# CTRL_MODULE_CORE register map
Vendor: Texas Instruments
Registers are 32-bit, access per field, reset 0x0 unless marked. A register's access mark holds for its fields unless they carry their own. Offsets are as the file gives them; [hi:lo] are bit positions; {n}, {i} and the like mark numbered series; 'fields as' and 'values as' point back to an identical list.

## CTRL_MODULE_CORE (part 12 of 12)
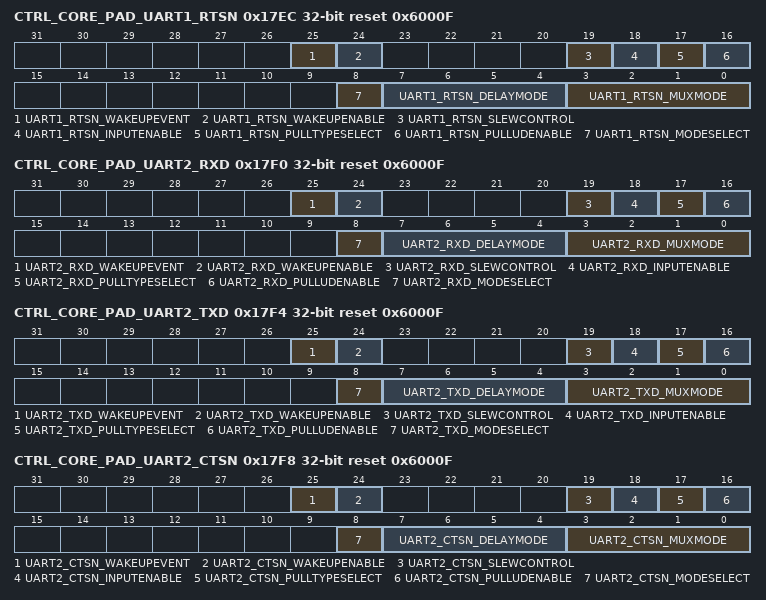
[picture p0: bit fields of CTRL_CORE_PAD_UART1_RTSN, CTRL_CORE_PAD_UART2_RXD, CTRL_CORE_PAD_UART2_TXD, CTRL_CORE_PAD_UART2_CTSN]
0x17EC CTRL_CORE_PAD_UART1_RTSN reset 0x6000F
  [25] UART1_RTSN_WAKEUPEVENT ro
    0=NOWAKEUP (No wakeup event detected); 1=WAKEUP (Wakeup event detected)
  [24] UART1_RTSN_WAKEUPENABLE rw
    0=DISABLE (Wakeup is disabled); 1=ENABLE (Wakeup is enabled)
  [19] UART1_RTSN_SLEWCONTROL rw
    0=FAST_SLEW (Fast slew is selected); 1=SLOW_SLEW (Slow slew is selected)
  [18] UART1_RTSN_INPUTENABLE rw
    0=DISABLE (Receive mode is disabled); 1=ENABLE (Receive mode is enabled)
  [17] UART1_RTSN_PULLTYPESELECT rw
    0=PULL_DOWN (Pull Down is selected); 1=PULL_UP (Pull Up is selected)
  [16] UART1_RTSN_PULLUDENABLE rw
    0=ENABLE (Enables weak Pull Up/Down); 1=DISABLE (Disables weak Pull Up/Down)
  [8] UART1_RTSN_MODESELECT rw — Selects between the Default IO Timing Mode and a Virtual or Manual IO Timing Mode. Refer to the device Data Manual for definition of the required settings for a given mode of operation. When this bit is 0b1, a Virtual IO Timing Mode can be selected via the DELAYMODE field of this register, as described in, Virtual IO Timing Modes. Manual IO Timing Modes are selected via the procedure described in , Manual IO Timing Modes.
    0=MUX_MODE (Default IO Timing Mode is used); 1=DELAY_MODE (A Virtual or Manual IO Timing Mode is used)
  [7:4] UART1_RTSN_DELAYMODE rw — This bit field selects the Virtual Timing Mode used when the MODESELECT bit is set to 0b1. See, Virtual IO Timing Modes for details.
  [3:0] UART1_RTSN_MUXMODE rw
    0=UART1_RTSN; 2=UART9_TXD; 3=MMC4_CMD; 14=GPIO7_25; 15=DRIVER OFF
0x17F0 CTRL_CORE_PAD_UART2_RXD reset 0x6000F
  [25] UART2_RXD_WAKEUPEVENT ro
    values as CTRL_CORE_PAD_UART1_RTSN.UART1_RTSN_WAKEUPEVENT
  [24] UART2_RXD_WAKEUPENABLE rw
    0=DISABLE (Wakeup is disabled); 1=ENABLE (Wakeup is enabled)
  [19] UART2_RXD_SLEWCONTROL rw
    values as CTRL_CORE_PAD_UART1_RTSN.UART1_RTSN_SLEWCONTROL
  [18] UART2_RXD_INPUTENABLE rw
    values as CTRL_CORE_PAD_UART1_RTSN.UART1_RTSN_INPUTENABLE
  [17] UART2_RXD_PULLTYPESELECT rw
    values as CTRL_CORE_PAD_UART1_RTSN.UART1_RTSN_PULLTYPESELECT
  [16] UART2_RXD_PULLUDENABLE rw
    values as CTRL_CORE_PAD_UART1_RTSN.UART1_RTSN_PULLUDENABLE
  [8] UART2_RXD_MODESELECT rw — Selects between the Default IO Timing Mode and a Virtual or Manual IO Timing Mode. Refer to the device Data Manual for definition of the required settings for a given mode of operation. When this bit is 0b1, a Virtual IO Timing Mode can be selected via the DELAYMODE field of this register, as described in, Virtual IO Timing Modes. Manual IO Timing Modes are selected via the procedure described in , Manual IO Timing Modes.
    values as CTRL_CORE_PAD_UART1_RTSN.UART1_RTSN_MODESELECT
  [7:4] UART2_RXD_DELAYMODE rw — This bit field selects the Virtual Timing Mode used when the MODESELECT bit is set to 0b1. See, Virtual IO Timing Modes for details.
  [3:0] UART2_RXD_MUXMODE rw
    1=UART3_CTSN; 2=UART3_RCTX; 3=MMC4_DAT0; 4=UART2_RXD; 5=UART1_DCDN; 14=GPIO7_26; 15=DRIVER OFF
0x17F4 CTRL_CORE_PAD_UART2_TXD reset 0x6000F
  [25] UART2_TXD_WAKEUPEVENT ro
    values as CTRL_CORE_PAD_UART1_RTSN.UART1_RTSN_WAKEUPEVENT
  [24] UART2_TXD_WAKEUPENABLE rw
    0=DISABLE (Wakeup is disabled); 1=ENABLE (Wakeup is enabled)
  [19] UART2_TXD_SLEWCONTROL rw
    values as CTRL_CORE_PAD_UART1_RTSN.UART1_RTSN_SLEWCONTROL
  [18] UART2_TXD_INPUTENABLE rw
    values as CTRL_CORE_PAD_UART1_RTSN.UART1_RTSN_INPUTENABLE
  [17] UART2_TXD_PULLTYPESELECT rw
    values as CTRL_CORE_PAD_UART1_RTSN.UART1_RTSN_PULLTYPESELECT
  [16] UART2_TXD_PULLUDENABLE rw
    values as CTRL_CORE_PAD_UART1_RTSN.UART1_RTSN_PULLUDENABLE
  [8] UART2_TXD_MODESELECT rw — Selects between the Default IO Timing Mode and a Virtual or Manual IO Timing Mode. Refer to the device Data Manual for definition of the required settings for a given mode of operation. When this bit is 0b1, a Virtual IO Timing Mode can be selected via the DELAYMODE field of this register, as described in, Virtual IO Timing Modes. Manual IO Timing Modes are selected via the procedure described in , Manual IO Timing Modes.
    values as CTRL_CORE_PAD_UART1_RTSN.UART1_RTSN_MODESELECT
  [7:4] UART2_TXD_DELAYMODE rw — This bit field selects the Virtual Timing Mode used when the MODESELECT bit is set to 0b1. See, Virtual IO Timing Modes for details.
  [3:0] UART2_TXD_MUXMODE rw
    0=UART2_TXD; 1=UART3_RTSN; 2=UART3_SD; 3=MMC4_DAT1; 4=UART2_TXD; 5=UART1_DSRN; 14=GPIO7_27; 15=DRIVER OFF
0x17F8 CTRL_CORE_PAD_UART2_CTSN reset 0x6000F
  [25] UART2_CTSN_WAKEUPEVENT ro
    values as CTRL_CORE_PAD_UART1_RTSN.UART1_RTSN_WAKEUPEVENT
  [24] UART2_CTSN_WAKEUPENABLE rw
    0=DISABLE (Wakeup is disabled); 1=ENABLE (Wakeup is enabled)
  [19] UART2_CTSN_SLEWCONTROL rw
    values as CTRL_CORE_PAD_UART1_RTSN.UART1_RTSN_SLEWCONTROL
  [18] UART2_CTSN_INPUTENABLE rw
    values as CTRL_CORE_PAD_UART1_RTSN.UART1_RTSN_INPUTENABLE
  [17] UART2_CTSN_PULLTYPESELECT rw
    values as CTRL_CORE_PAD_UART1_RTSN.UART1_RTSN_PULLTYPESELECT
  [16] UART2_CTSN_PULLUDENABLE rw
    values as CTRL_CORE_PAD_UART1_RTSN.UART1_RTSN_PULLUDENABLE
  [8] UART2_CTSN_MODESELECT rw — Selects between the Default IO Timing Mode and a Virtual or Manual IO Timing Mode. Refer to the device Data Manual for definition of the required settings for a given mode of operation. When this bit is 0b1, a Virtual IO Timing Mode can be selected via the DELAYMODE field of this register, as described in, Virtual IO Timing Modes. Manual IO Timing Modes are selected via the procedure described in , Manual IO Timing Modes.
    values as CTRL_CORE_PAD_UART1_RTSN.UART1_RTSN_MODESELECT
  [7:4] UART2_CTSN_DELAYMODE rw — This bit field selects the Virtual Timing Mode used when the MODESELECT bit is set to 0b1. See, Virtual IO Timing Modes for details.
  [3:0] UART2_CTSN_MUXMODE rw
    0=UART2_CTSN; 2=UART3_RXD; 3=MMC4_DAT2; 4=UART10_RXD; 5=UART1_DTRN; 14=GPIO1_16; 15=DRIVER OFF
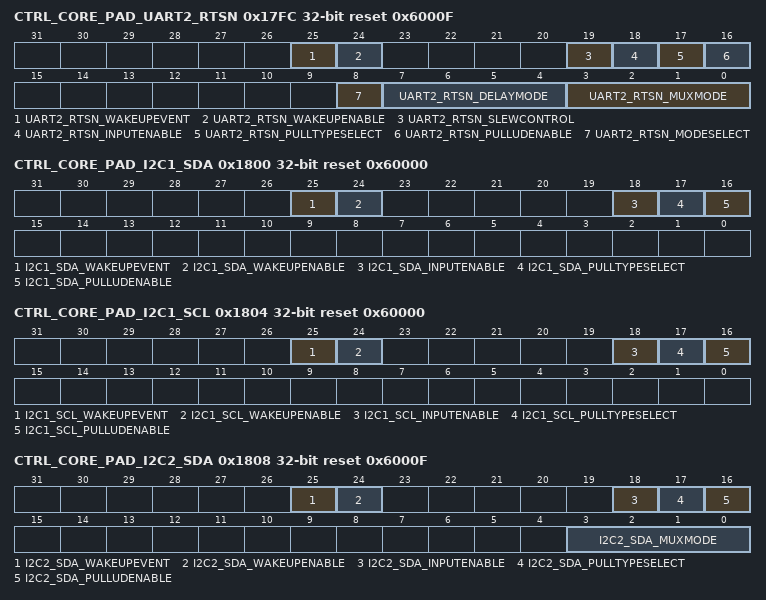
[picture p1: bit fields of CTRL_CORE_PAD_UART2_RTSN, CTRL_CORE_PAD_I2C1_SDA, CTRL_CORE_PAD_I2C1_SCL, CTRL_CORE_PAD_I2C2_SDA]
0x17FC CTRL_CORE_PAD_UART2_RTSN reset 0x6000F
  [25] UART2_RTSN_WAKEUPEVENT ro
    values as CTRL_CORE_PAD_UART1_RTSN.UART1_RTSN_WAKEUPEVENT
  [24] UART2_RTSN_WAKEUPENABLE rw
    0=DISABLE (Wakeup is disabled); 1=ENABLE (Wakeup is enabled)
  [19] UART2_RTSN_SLEWCONTROL rw
    values as CTRL_CORE_PAD_UART1_RTSN.UART1_RTSN_SLEWCONTROL
  [18] UART2_RTSN_INPUTENABLE rw
    values as CTRL_CORE_PAD_UART1_RTSN.UART1_RTSN_INPUTENABLE
  [17] UART2_RTSN_PULLTYPESELECT rw
    values as CTRL_CORE_PAD_UART1_RTSN.UART1_RTSN_PULLTYPESELECT
  [16] UART2_RTSN_PULLUDENABLE rw
    values as CTRL_CORE_PAD_UART1_RTSN.UART1_RTSN_PULLUDENABLE
  [8] UART2_RTSN_MODESELECT rw — Selects between the Default IO Timing Mode and a Virtual or Manual IO Timing Mode. Refer to the device Data Manual for definition of the required settings for a given mode of operation. When this bit is 0b1, a Virtual IO Timing Mode can be selected via the DELAYMODE field of this register, as described in, Virtual IO Timing Modes. Manual IO Timing Modes are selected via the procedure described in , Manual IO Timing Modes.
    values as CTRL_CORE_PAD_UART1_RTSN.UART1_RTSN_MODESELECT
  [7:4] UART2_RTSN_DELAYMODE rw — This bit field selects the Virtual Timing Mode used when the MODESELECT bit is set to 0b1. See, Virtual IO Timing Modes for details.
  [3:0] UART2_RTSN_MUXMODE rw
    0=UART2_RTSN; 1=UART3_TXD; 2=UART3_IRTX; 3=MMC4_DAT3; 4=UART10_TXD; 5=UART1_RIN; 14=GPIO1_17; 15=DRIVER OFF
0x1800 CTRL_CORE_PAD_I2C1_SDA reset 0x60000
  [25] I2C1_SDA_WAKEUPEVENT ro
    values as CTRL_CORE_PAD_UART1_RTSN.UART1_RTSN_WAKEUPEVENT
  [24] I2C1_SDA_WAKEUPENABLE rw
    0=DISABLE (Wakeup is disabled); 1=ENABLE (Wakeup is enabled)
  [18] I2C1_SDA_INPUTENABLE rw
    values as CTRL_CORE_PAD_UART1_RTSN.UART1_RTSN_INPUTENABLE
  [17] I2C1_SDA_PULLTYPESELECT rw
    values as CTRL_CORE_PAD_UART1_RTSN.UART1_RTSN_PULLTYPESELECT
  [16] I2C1_SDA_PULLUDENABLE rw
    values as CTRL_CORE_PAD_UART1_RTSN.UART1_RTSN_PULLUDENABLE
0x1804 CTRL_CORE_PAD_I2C1_SCL reset 0x60000
  [25] I2C1_SCL_WAKEUPEVENT ro
    values as CTRL_CORE_PAD_UART1_RTSN.UART1_RTSN_WAKEUPEVENT
  [24] I2C1_SCL_WAKEUPENABLE rw
    0=DISABLE (Wakeup is disabled); 1=ENABLE (Wakeup is enabled)
  [18] I2C1_SCL_INPUTENABLE rw
    values as CTRL_CORE_PAD_UART1_RTSN.UART1_RTSN_INPUTENABLE
  [17] I2C1_SCL_PULLTYPESELECT rw
    values as CTRL_CORE_PAD_UART1_RTSN.UART1_RTSN_PULLTYPESELECT
  [16] I2C1_SCL_PULLUDENABLE rw
    values as CTRL_CORE_PAD_UART1_RTSN.UART1_RTSN_PULLUDENABLE
0x1808 CTRL_CORE_PAD_I2C2_SDA reset 0x6000F
  [25] I2C2_SDA_WAKEUPEVENT ro
    values as CTRL_CORE_PAD_UART1_RTSN.UART1_RTSN_WAKEUPEVENT
  [24] I2C2_SDA_WAKEUPENABLE rw
    0=DISABLE (Wakeup is disabled); 1=ENABLE (Wakeup is enabled)
  [18] I2C2_SDA_INPUTENABLE rw
    values as CTRL_CORE_PAD_UART1_RTSN.UART1_RTSN_INPUTENABLE
  [17] I2C2_SDA_PULLTYPESELECT rw
    values as CTRL_CORE_PAD_UART1_RTSN.UART1_RTSN_PULLTYPESELECT
  [16] I2C2_SDA_PULLUDENABLE rw
    values as CTRL_CORE_PAD_UART1_RTSN.UART1_RTSN_PULLUDENABLE
  [3:0] I2C2_SDA_MUXMODE rw
    0=I2C2_SDA; 1=HDMI1_DDC_SCL; 15=DRIVER OFF
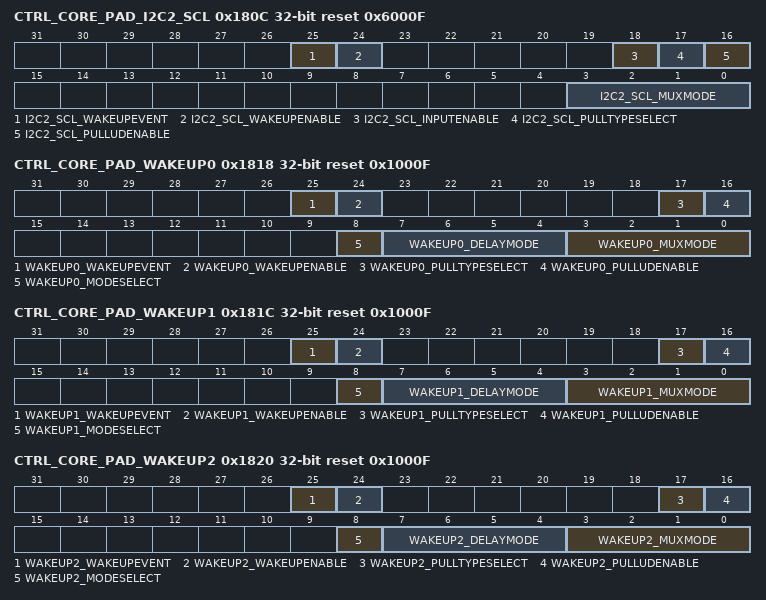
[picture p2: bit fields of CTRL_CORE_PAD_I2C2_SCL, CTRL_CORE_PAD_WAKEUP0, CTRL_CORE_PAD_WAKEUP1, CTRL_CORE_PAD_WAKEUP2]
0x180C CTRL_CORE_PAD_I2C2_SCL reset 0x6000F
  [25] I2C2_SCL_WAKEUPEVENT ro
    values as CTRL_CORE_PAD_UART1_RTSN.UART1_RTSN_WAKEUPEVENT
  [24] I2C2_SCL_WAKEUPENABLE rw
    0=DISABLE (Wakeup is disabled); 1=ENABLE (Wakeup is enabled)
  [18] I2C2_SCL_INPUTENABLE rw
    values as CTRL_CORE_PAD_UART1_RTSN.UART1_RTSN_INPUTENABLE
  [17] I2C2_SCL_PULLTYPESELECT rw
    values as CTRL_CORE_PAD_UART1_RTSN.UART1_RTSN_PULLTYPESELECT
  [16] I2C2_SCL_PULLUDENABLE rw
    values as CTRL_CORE_PAD_UART1_RTSN.UART1_RTSN_PULLUDENABLE
  [3:0] I2C2_SCL_MUXMODE rw
    0=I2C2_SCL; 1=HDMI1_DDC_SDA; 15=DRIVER OFF
0x1818 CTRL_CORE_PAD_WAKEUP0 reset 0x1000F
  [25] WAKEUP0_WAKEUPEVENT ro
    values as CTRL_CORE_PAD_UART1_RTSN.UART1_RTSN_WAKEUPEVENT
  [24] WAKEUP0_WAKEUPENABLE rw
    0=DISABLE (Wakeup is disabled); 1=ENABLE (Wakeup is enabled)
  [17] WAKEUP0_PULLTYPESELECT rw
    values as CTRL_CORE_PAD_UART1_RTSN.UART1_RTSN_PULLTYPESELECT
  [16] WAKEUP0_PULLUDENABLE rw
    values as CTRL_CORE_PAD_UART1_RTSN.UART1_RTSN_PULLUDENABLE
  [8] WAKEUP0_MODESELECT rw — Selects between the Default IO Timing Mode and a Virtual or Manual IO Timing Mode. Refer to the device Data Manual for definition of the required settings for a given mode of operation. When this bit is 0b1, a Virtual IO Timing Mode can be selected via the DELAYMODE field of this register, as described in, Virtual IO Timing Modes. Manual IO Timing Modes are selected via the procedure described in , Manual IO Timing Modes.
    values as CTRL_CORE_PAD_UART1_RTSN.UART1_RTSN_MODESELECT
  [7:4] WAKEUP0_DELAYMODE rw — This bit field selects the Virtual Timing Mode used when the MODESELECT bit is set to 0b1. See, Virtual IO Timing Modes for details.
  [3:0] WAKEUP0_MUXMODE rw
    0=WAKEUP0; 1=DCAN1_RX; 14=GPIO1_0; 15=DRIVER OFF
0x181C CTRL_CORE_PAD_WAKEUP1 reset 0x1000F
  [25] WAKEUP1_WAKEUPEVENT ro
    values as CTRL_CORE_PAD_UART1_RTSN.UART1_RTSN_WAKEUPEVENT
  [24] WAKEUP1_WAKEUPENABLE rw
    0=DISABLE (Wakeup is disabled); 1=ENABLE (Wakeup is enabled)
  [17] WAKEUP1_PULLTYPESELECT rw
    values as CTRL_CORE_PAD_UART1_RTSN.UART1_RTSN_PULLTYPESELECT
  [16] WAKEUP1_PULLUDENABLE rw
    values as CTRL_CORE_PAD_UART1_RTSN.UART1_RTSN_PULLUDENABLE
  [8] WAKEUP1_MODESELECT rw — Selects between the Default IO Timing Mode and a Virtual or Manual IO Timing Mode. Refer to the device Data Manual for definition of the required settings for a given mode of operation. When this bit is 0b1, a Virtual IO Timing Mode can be selected via the DELAYMODE field of this register, as described in, Virtual IO Timing Modes. Manual IO Timing Modes are selected via the procedure described in , Manual IO Timing Modes.
    values as CTRL_CORE_PAD_UART1_RTSN.UART1_RTSN_MODESELECT
  [7:4] WAKEUP1_DELAYMODE rw — This bit field selects the Virtual Timing Mode used when the MODESELECT bit is set to 0b1. See, Virtual IO Timing Modes for details.
  [3:0] WAKEUP1_MUXMODE rw
    0=WAKEUP1; 1=DCAN2_RX; 14=GPIO1_1; 15=DRIVER OFF
0x1820 CTRL_CORE_PAD_WAKEUP2 reset 0x1000F
  [25] WAKEUP2_WAKEUPEVENT ro
    values as CTRL_CORE_PAD_UART1_RTSN.UART1_RTSN_WAKEUPEVENT
  [24] WAKEUP2_WAKEUPENABLE rw
    0=DISABLE (Wakeup is disabled); 1=ENABLE (Wakeup is enabled)
  [17] WAKEUP2_PULLTYPESELECT rw
    values as CTRL_CORE_PAD_UART1_RTSN.UART1_RTSN_PULLTYPESELECT
  [16] WAKEUP2_PULLUDENABLE rw
    values as CTRL_CORE_PAD_UART1_RTSN.UART1_RTSN_PULLUDENABLE
  [8] WAKEUP2_MODESELECT rw — Selects between the Default IO Timing Mode and a Virtual or Manual IO Timing Mode. Refer to the device Data Manual for definition of the required settings for a given mode of operation. When this bit is 0b1, a Virtual IO Timing Mode can be selected via the DELAYMODE field of this register, as described in, Virtual IO Timing Modes. Manual IO Timing Modes are selected via the procedure described in , Manual IO Timing Modes.
    values as CTRL_CORE_PAD_UART1_RTSN.UART1_RTSN_MODESELECT
  [7:4] WAKEUP2_DELAYMODE rw — This bit field selects the Virtual Timing Mode used when the MODESELECT bit is set to 0b1. See, Virtual IO Timing Modes for details.
  [3:0] WAKEUP2_MUXMODE rw
    0=WAKEUP2; 1=SYS_NIRQ2; 14=GPIO1_2; 15=DRIVER OFF
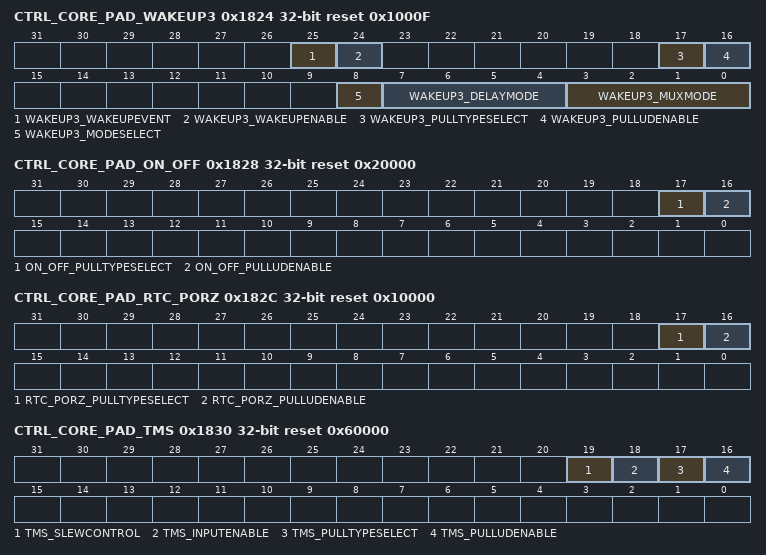
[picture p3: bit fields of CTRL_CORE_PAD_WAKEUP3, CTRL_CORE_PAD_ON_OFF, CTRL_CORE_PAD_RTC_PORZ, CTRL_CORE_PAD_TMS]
0x1824 CTRL_CORE_PAD_WAKEUP3 reset 0x1000F
  [25] WAKEUP3_WAKEUPEVENT ro
    values as CTRL_CORE_PAD_UART1_RTSN.UART1_RTSN_WAKEUPEVENT
  [24] WAKEUP3_WAKEUPENABLE rw
    0=DISABLE (Wakeup is disabled); 1=ENABLE (Wakeup is enabled)
  [17] WAKEUP3_PULLTYPESELECT rw
    values as CTRL_CORE_PAD_UART1_RTSN.UART1_RTSN_PULLTYPESELECT
  [16] WAKEUP3_PULLUDENABLE rw
    values as CTRL_CORE_PAD_UART1_RTSN.UART1_RTSN_PULLUDENABLE
  [8] WAKEUP3_MODESELECT rw — Selects between the Default IO Timing Mode and a Virtual or Manual IO Timing Mode. Refer to the device Data Manual for definition of the required settings for a given mode of operation. When this bit is 0b1, a Virtual IO Timing Mode can be selected via the DELAYMODE field of this register, as described in, Virtual IO Timing Modes. Manual IO Timing Modes are selected via the procedure described in , Manual IO Timing Modes.
    values as CTRL_CORE_PAD_UART1_RTSN.UART1_RTSN_MODESELECT
  [7:4] WAKEUP3_DELAYMODE rw — This bit field selects the Virtual Timing Mode used when the MODESELECT bit is set to 0b1. See, Virtual IO Timing Modes for details.
  [3:0] WAKEUP3_MUXMODE rw
    0=WAKEUP3; 1=SYS_NIRQ1; 14=GPIO1_3; 15=DRIVER OFF
0x1828 CTRL_CORE_PAD_ON_OFF reset 0x20000
  [17] ON_OFF_PULLTYPESELECT rw
    values as CTRL_CORE_PAD_UART1_RTSN.UART1_RTSN_PULLTYPESELECT
  [16] ON_OFF_PULLUDENABLE rw
    values as CTRL_CORE_PAD_UART1_RTSN.UART1_RTSN_PULLUDENABLE
0x182C CTRL_CORE_PAD_RTC_PORZ reset 0x10000
  [17] RTC_PORZ_PULLTYPESELECT rw
    values as CTRL_CORE_PAD_UART1_RTSN.UART1_RTSN_PULLTYPESELECT
  [16] RTC_PORZ_PULLUDENABLE rw
    values as CTRL_CORE_PAD_UART1_RTSN.UART1_RTSN_PULLUDENABLE
0x1830 CTRL_CORE_PAD_TMS reset 0x60000
  [19] TMS_SLEWCONTROL rw
    values as CTRL_CORE_PAD_UART1_RTSN.UART1_RTSN_SLEWCONTROL
  [18] TMS_INPUTENABLE rw
    values as CTRL_CORE_PAD_UART1_RTSN.UART1_RTSN_INPUTENABLE
  [17] TMS_PULLTYPESELECT rw
    values as CTRL_CORE_PAD_UART1_RTSN.UART1_RTSN_PULLTYPESELECT
  [16] TMS_PULLUDENABLE rw
    values as CTRL_CORE_PAD_UART1_RTSN.UART1_RTSN_PULLUDENABLE
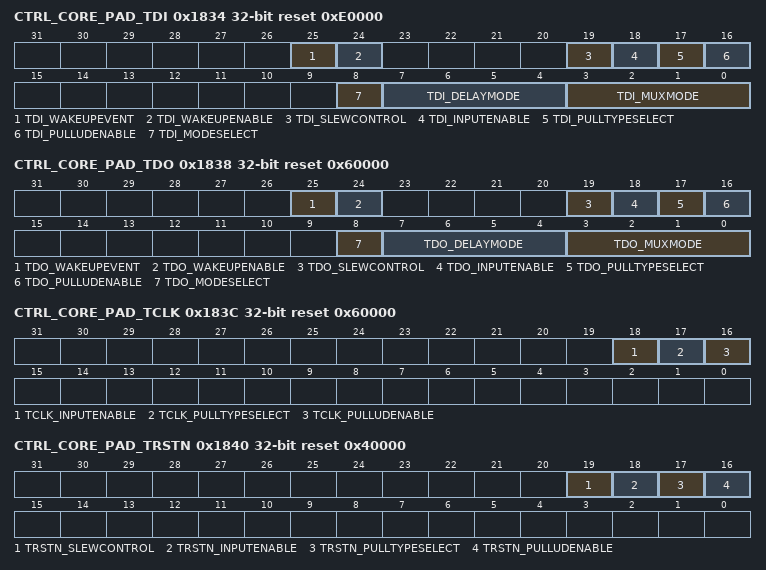
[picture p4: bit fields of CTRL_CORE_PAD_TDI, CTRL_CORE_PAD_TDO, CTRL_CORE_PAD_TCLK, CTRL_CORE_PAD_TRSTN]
0x1834 CTRL_CORE_PAD_TDI reset 0xE0000
  [25] TDI_WAKEUPEVENT ro
    values as CTRL_CORE_PAD_UART1_RTSN.UART1_RTSN_WAKEUPEVENT
  [24] TDI_WAKEUPENABLE rw
    0=DISABLE (Wakeup is disabled); 1=ENABLE (Wakeup is enabled)
  [19] TDI_SLEWCONTROL rw
    values as CTRL_CORE_PAD_UART1_RTSN.UART1_RTSN_SLEWCONTROL
  [18] TDI_INPUTENABLE rw
    values as CTRL_CORE_PAD_UART1_RTSN.UART1_RTSN_INPUTENABLE
  [17] TDI_PULLTYPESELECT rw
    values as CTRL_CORE_PAD_UART1_RTSN.UART1_RTSN_PULLTYPESELECT
  [16] TDI_PULLUDENABLE rw
    values as CTRL_CORE_PAD_UART1_RTSN.UART1_RTSN_PULLUDENABLE
  [8] TDI_MODESELECT rw — Selects between the Default IO Timing Mode and a Virtual or Manual IO Timing Mode. Refer to the device Data Manual for definition of the required settings for a given mode of operation. When this bit is 0b1, a Virtual IO Timing Mode can be selected via the DELAYMODE field of this register, as described in, Virtual IO Timing Modes. Manual IO Timing Modes are selected via the procedure described in , Manual IO Timing Modes.
    values as CTRL_CORE_PAD_UART1_RTSN.UART1_RTSN_MODESELECT
  [7:4] TDI_DELAYMODE rw — This bit field selects the Virtual Timing Mode used when the MODESELECT bit is set to 0b1. See, Virtual IO Timing Modes for details.
  [3:0] TDI_MUXMODE rw
    0=TDI; 14=GPIO8_27
0x1838 CTRL_CORE_PAD_TDO reset 0x60000
  [25] TDO_WAKEUPEVENT ro
    values as CTRL_CORE_PAD_UART1_RTSN.UART1_RTSN_WAKEUPEVENT
  [24] TDO_WAKEUPENABLE rw
    0=DISABLE (Wakeup is disabled); 1=ENABLE (Wakeup is enabled)
  [19] TDO_SLEWCONTROL rw
    values as CTRL_CORE_PAD_UART1_RTSN.UART1_RTSN_SLEWCONTROL
  [18] TDO_INPUTENABLE rw
    values as CTRL_CORE_PAD_UART1_RTSN.UART1_RTSN_INPUTENABLE
  [17] TDO_PULLTYPESELECT rw
    values as CTRL_CORE_PAD_UART1_RTSN.UART1_RTSN_PULLTYPESELECT
  [16] TDO_PULLUDENABLE rw
    values as CTRL_CORE_PAD_UART1_RTSN.UART1_RTSN_PULLUDENABLE
  [8] TDO_MODESELECT rw — Selects between the Default IO Timing Mode and a Virtual or Manual IO Timing Mode. Refer to the device Data Manual for definition of the required settings for a given mode of operation. When this bit is 0b1, a Virtual IO Timing Mode can be selected via the DELAYMODE field of this register, as described in, Virtual IO Timing Modes. Manual IO Timing Modes are selected via the procedure described in , Manual IO Timing Modes.
    values as CTRL_CORE_PAD_UART1_RTSN.UART1_RTSN_MODESELECT
  [7:4] TDO_DELAYMODE rw — This bit field selects the Virtual Timing Mode used when the MODESELECT bit is set to 0b1. See, Virtual IO Timing Modes for details.
  [3:0] TDO_MUXMODE rw
    0=TDO; 14=GPIO8_28
0x183C CTRL_CORE_PAD_TCLK reset 0x60000
  [18] TCLK_INPUTENABLE rw
    values as CTRL_CORE_PAD_UART1_RTSN.UART1_RTSN_INPUTENABLE
  [17] TCLK_PULLTYPESELECT rw
    values as CTRL_CORE_PAD_UART1_RTSN.UART1_RTSN_PULLTYPESELECT
  [16] TCLK_PULLUDENABLE rw
    values as CTRL_CORE_PAD_UART1_RTSN.UART1_RTSN_PULLUDENABLE
0x1840 CTRL_CORE_PAD_TRSTN reset 0x40000
  [19] TRSTN_SLEWCONTROL rw
    values as CTRL_CORE_PAD_UART1_RTSN.UART1_RTSN_SLEWCONTROL
  [18] TRSTN_INPUTENABLE rw
    values as CTRL_CORE_PAD_UART1_RTSN.UART1_RTSN_INPUTENABLE
  [17] TRSTN_PULLTYPESELECT rw
    values as CTRL_CORE_PAD_UART1_RTSN.UART1_RTSN_PULLTYPESELECT
  [16] TRSTN_PULLUDENABLE rw
    values as CTRL_CORE_PAD_UART1_RTSN.UART1_RTSN_PULLUDENABLE
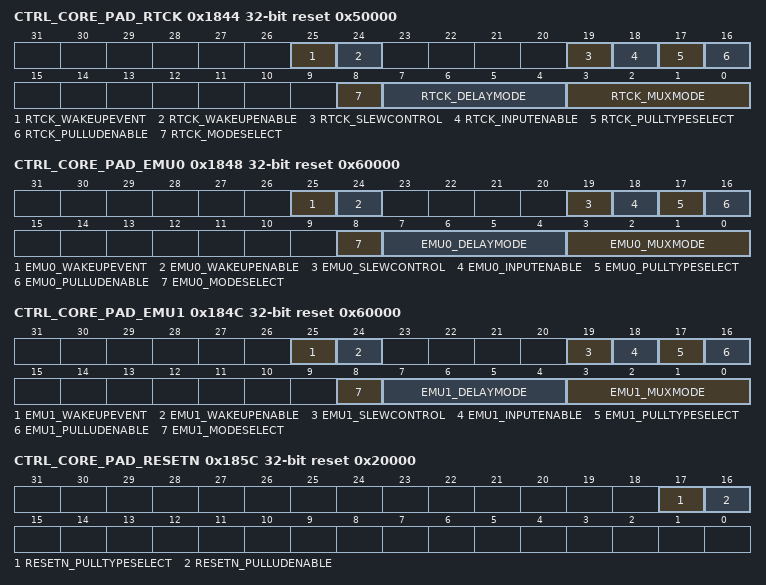
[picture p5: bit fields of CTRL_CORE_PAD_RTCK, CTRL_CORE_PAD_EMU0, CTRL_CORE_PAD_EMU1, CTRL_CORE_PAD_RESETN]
0x1844 CTRL_CORE_PAD_RTCK reset 0x50000
  [25] RTCK_WAKEUPEVENT ro
    values as CTRL_CORE_PAD_UART1_RTSN.UART1_RTSN_WAKEUPEVENT
  [24] RTCK_WAKEUPENABLE rw
    0=DISABLE (Wakeup is disabled); 1=ENABLE (Wakeup is enabled)
  [19] RTCK_SLEWCONTROL rw
    values as CTRL_CORE_PAD_UART1_RTSN.UART1_RTSN_SLEWCONTROL
  [18] RTCK_INPUTENABLE rw
    values as CTRL_CORE_PAD_UART1_RTSN.UART1_RTSN_INPUTENABLE
  [17] RTCK_PULLTYPESELECT rw
    values as CTRL_CORE_PAD_UART1_RTSN.UART1_RTSN_PULLTYPESELECT
  [16] RTCK_PULLUDENABLE rw
    values as CTRL_CORE_PAD_UART1_RTSN.UART1_RTSN_PULLUDENABLE
  [8] RTCK_MODESELECT rw — Selects between the Default IO Timing Mode and a Virtual or Manual IO Timing Mode. Refer to the device Data Manual for definition of the required settings for a given mode of operation. When this bit is 0b1, a Virtual IO Timing Mode can be selected via the DELAYMODE field of this register, as described in, Virtual IO Timing Modes. Manual IO Timing Modes are selected via the procedure described in , Manual IO Timing Modes.
    values as CTRL_CORE_PAD_UART1_RTSN.UART1_RTSN_MODESELECT
  [7:4] RTCK_DELAYMODE rw — This bit field selects the Virtual Timing Mode used when the MODESELECT bit is set to 0b1. See, Virtual IO Timing Modes for details.
  [3:0] RTCK_MUXMODE rw
    0=RTCK; 14=GPIO8_29
0x1848 CTRL_CORE_PAD_EMU0 reset 0x60000
  [25] EMU0_WAKEUPEVENT ro
    values as CTRL_CORE_PAD_UART1_RTSN.UART1_RTSN_WAKEUPEVENT
  [24] EMU0_WAKEUPENABLE rw
    0=DISABLE (Wakeup is disabled); 1=ENABLE (Wakeup is enabled)
  [19] EMU0_SLEWCONTROL rw
    values as CTRL_CORE_PAD_UART1_RTSN.UART1_RTSN_SLEWCONTROL
  [18] EMU0_INPUTENABLE rw
    values as CTRL_CORE_PAD_UART1_RTSN.UART1_RTSN_INPUTENABLE
  [17] EMU0_PULLTYPESELECT rw
    values as CTRL_CORE_PAD_UART1_RTSN.UART1_RTSN_PULLTYPESELECT
  [16] EMU0_PULLUDENABLE rw
    values as CTRL_CORE_PAD_UART1_RTSN.UART1_RTSN_PULLUDENABLE
  [8] EMU0_MODESELECT rw — Selects between the Default IO Timing Mode and a Virtual or Manual IO Timing Mode. Refer to the device Data Manual for definition of the required settings for a given mode of operation. When this bit is 0b1, a Virtual IO Timing Mode can be selected via the DELAYMODE field of this register, as described in, Virtual IO Timing Modes. Manual IO Timing Modes are selected via the procedure described in , Manual IO Timing Modes.
    values as CTRL_CORE_PAD_UART1_RTSN.UART1_RTSN_MODESELECT
  [7:4] EMU0_DELAYMODE rw — This bit field selects the Virtual Timing Mode used when the MODESELECT bit is set to 0b1. See, Virtual IO Timing Modes for details.
  [3:0] EMU0_MUXMODE rw
    0=EMU0; 14=GPIO8_30
0x184C CTRL_CORE_PAD_EMU1 reset 0x60000
  [25] EMU1_WAKEUPEVENT ro
    values as CTRL_CORE_PAD_UART1_RTSN.UART1_RTSN_WAKEUPEVENT
  [24] EMU1_WAKEUPENABLE rw
    0=DISABLE (Wakeup is disabled); 1=ENABLE (Wakeup is enabled)
  [19] EMU1_SLEWCONTROL rw
    values as CTRL_CORE_PAD_UART1_RTSN.UART1_RTSN_SLEWCONTROL
  [18] EMU1_INPUTENABLE rw
    values as CTRL_CORE_PAD_UART1_RTSN.UART1_RTSN_INPUTENABLE
  [17] EMU1_PULLTYPESELECT rw
    values as CTRL_CORE_PAD_UART1_RTSN.UART1_RTSN_PULLTYPESELECT
  [16] EMU1_PULLUDENABLE rw
    values as CTRL_CORE_PAD_UART1_RTSN.UART1_RTSN_PULLUDENABLE
  [8] EMU1_MODESELECT rw — Selects between the Default IO Timing Mode and a Virtual or Manual IO Timing Mode. Refer to the device Data Manual for definition of the required settings for a given mode of operation. When this bit is 0b1, a Virtual IO Timing Mode can be selected via the DELAYMODE field of this register, as described in, Virtual IO Timing Modes. Manual IO Timing Modes are selected via the procedure described in , Manual IO Timing Modes.
    values as CTRL_CORE_PAD_UART1_RTSN.UART1_RTSN_MODESELECT
  [7:4] EMU1_DELAYMODE rw — This bit field selects the Virtual Timing Mode used when the MODESELECT bit is set to 0b1. See, Virtual IO Timing Modes for details.
  [3:0] EMU1_MUXMODE rw
    0=EMU1; 14=GPIO8_31
0x185C CTRL_CORE_PAD_RESETN reset 0x20000
  [17] RESETN_PULLTYPESELECT rw
    values as CTRL_CORE_PAD_UART1_RTSN.UART1_RTSN_PULLTYPESELECT
  [16] RESETN_PULLUDENABLE rw
    values as CTRL_CORE_PAD_UART1_RTSN.UART1_RTSN_PULLUDENABLE
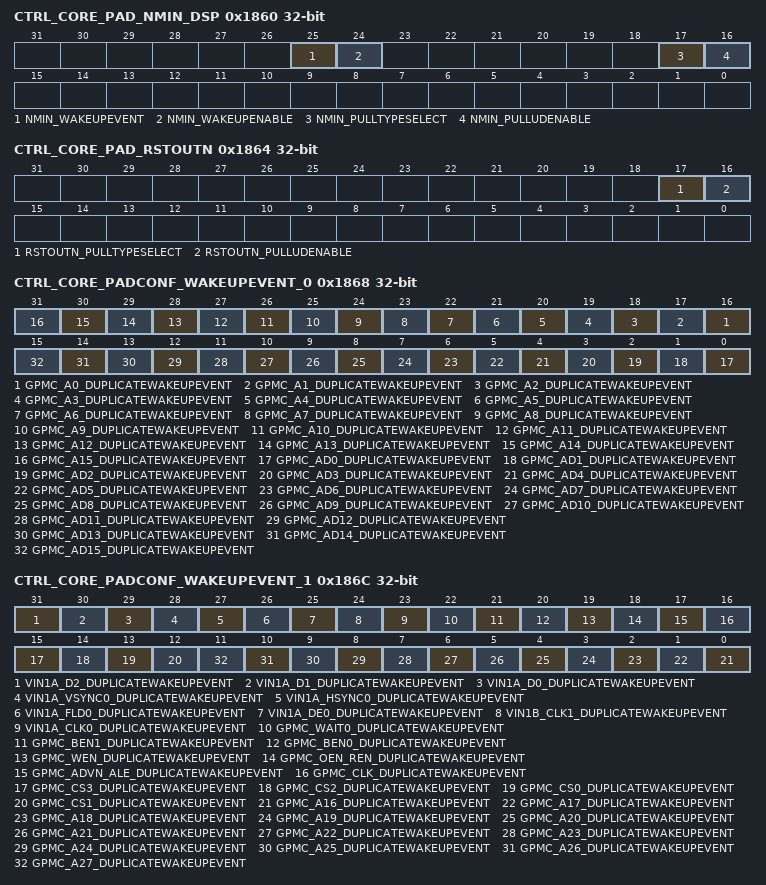
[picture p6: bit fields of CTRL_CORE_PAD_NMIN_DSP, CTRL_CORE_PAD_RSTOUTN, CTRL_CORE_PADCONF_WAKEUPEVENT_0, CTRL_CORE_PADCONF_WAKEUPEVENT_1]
0x1860 CTRL_CORE_PAD_NMIN_DSP
  [25] NMIN_WAKEUPEVENT ro
    values as CTRL_CORE_PAD_UART1_RTSN.UART1_RTSN_WAKEUPEVENT
  [24] NMIN_WAKEUPENABLE rw
    0=DISABLE (Wakeup is disabled); 1=ENABLE (Wakeup is enabled)
  [17] NMIN_PULLTYPESELECT rw
    values as CTRL_CORE_PAD_UART1_RTSN.UART1_RTSN_PULLTYPESELECT
  [16] NMIN_PULLUDENABLE rw
    values as CTRL_CORE_PAD_UART1_RTSN.UART1_RTSN_PULLUDENABLE
0x1864 CTRL_CORE_PAD_RSTOUTN
  [17] RSTOUTN_PULLTYPESELECT rw
    values as CTRL_CORE_PAD_UART1_RTSN.UART1_RTSN_PULLTYPESELECT
  [16] RSTOUTN_PULLUDENABLE rw
    values as CTRL_CORE_PAD_UART1_RTSN.UART1_RTSN_PULLUDENABLE
0x1868 CTRL_CORE_PADCONF_WAKEUPEVENT_0 ro
  [n+16] GPMC_A{n}_DUPLICATEWAKEUPEVENT (n=0..15), [n] GPMC_AD{n}_DUPLICATEWAKEUPEVENT (n=0..15)
0x186C CTRL_CORE_PADCONF_WAKEUPEVENT_1 ro
  [31] VIN1A_D2_DUPLICATEWAKEUPEVENT, [30] VIN1A_D1_DUPLICATEWAKEUPEVENT, [29] VIN1A_D0_DUPLICATEWAKEUPEVENT, [28] VIN1A_VSYNC0_DUPLICATEWAKEUPEVENT, [27] VIN1A_HSYNC0_DUPLICATEWAKEUPEVENT, [26] VIN1A_FLD0_DUPLICATEWAKEUPEVENT, [25] VIN1A_DE0_DUPLICATEWAKEUPEVENT, [24] VIN1B_CLK1_DUPLICATEWAKEUPEVENT, [23] VIN1A_CLK0_DUPLICATEWAKEUPEVENT, [22] GPMC_WAIT0_DUPLICATEWAKEUPEVENT, [21] GPMC_BEN1_DUPLICATEWAKEUPEVENT, [20] GPMC_BEN0_DUPLICATEWAKEUPEVENT, [19] GPMC_WEN_DUPLICATEWAKEUPEVENT, [18] GPMC_OEN_REN_DUPLICATEWAKEUPEVENT, [17] GPMC_ADVN_ALE_DUPLICATEWAKEUPEVENT, [16] GPMC_CLK_DUPLICATEWAKEUPEVENT, [15] GPMC_CS3_DUPLICATEWAKEUPEVENT, [14] GPMC_CS2_DUPLICATEWAKEUPEVENT, [13] GPMC_CS0_DUPLICATEWAKEUPEVENT, [12] GPMC_CS1_DUPLICATEWAKEUPEVENT, [n-16] GPMC_A{n}_DUPLICATEWAKEUPEVENT (n=16..27)
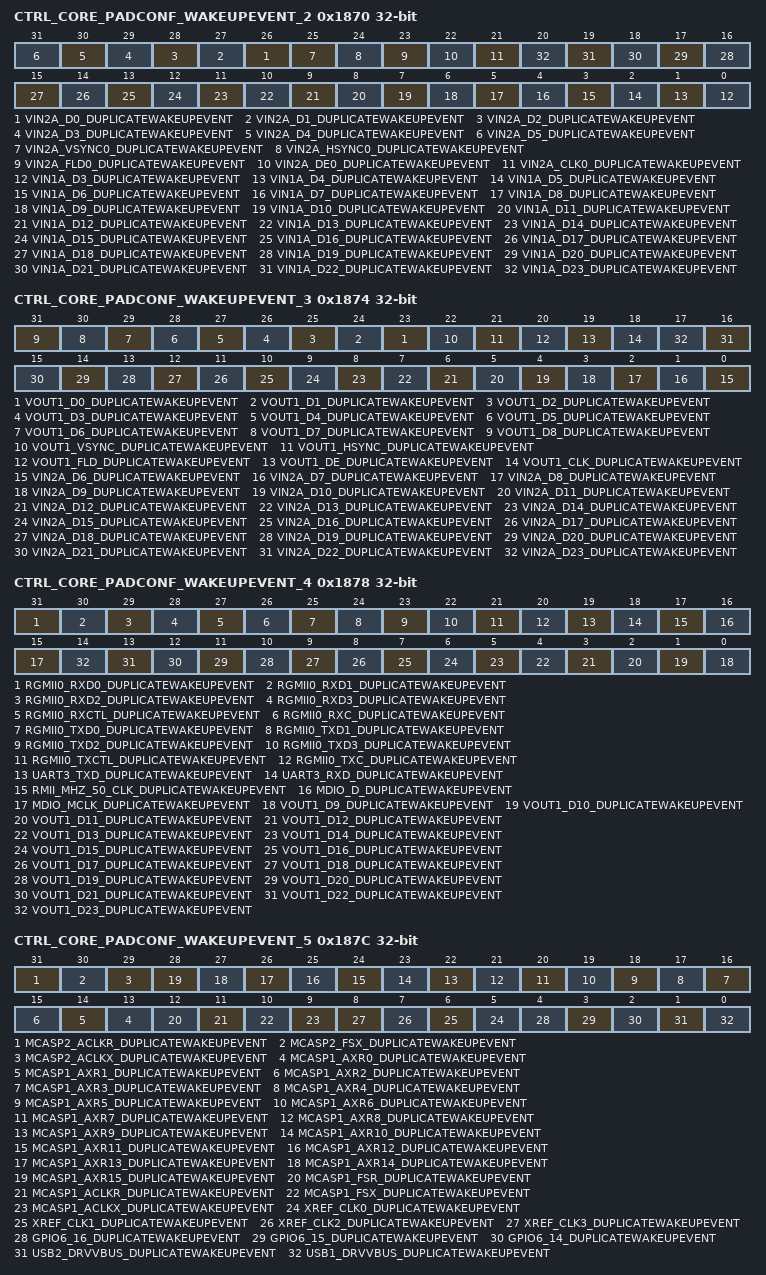
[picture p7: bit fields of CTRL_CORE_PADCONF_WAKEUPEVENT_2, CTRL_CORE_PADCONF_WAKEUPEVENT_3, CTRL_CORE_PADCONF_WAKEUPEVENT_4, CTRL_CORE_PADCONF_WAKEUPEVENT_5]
0x1870 CTRL_CORE_PADCONF_WAKEUPEVENT_2 ro
  [n+26] VIN2A_D{n}_DUPLICATEWAKEUPEVENT (n=0..5), [25] VIN2A_VSYNC0_DUPLICATEWAKEUPEVENT, [24] VIN2A_HSYNC0_DUPLICATEWAKEUPEVENT, [23] VIN2A_FLD0_DUPLICATEWAKEUPEVENT, [22] VIN2A_DE0_DUPLICATEWAKEUPEVENT, [21] VIN2A_CLK0_DUPLICATEWAKEUPEVENT, [n-3] VIN1A_D{n}_DUPLICATEWAKEUPEVENT (n=3..23)
0x1874 CTRL_CORE_PADCONF_WAKEUPEVENT_3 ro
  [n+23] VOUT1_D{n}_DUPLICATEWAKEUPEVENT (n=0..8), [22] VOUT1_VSYNC_DUPLICATEWAKEUPEVENT, [21] VOUT1_HSYNC_DUPLICATEWAKEUPEVENT, [20] VOUT1_FLD_DUPLICATEWAKEUPEVENT, [19] VOUT1_DE_DUPLICATEWAKEUPEVENT, [18] VOUT1_CLK_DUPLICATEWAKEUPEVENT, [n-6] VIN2A_D{n}_DUPLICATEWAKEUPEVENT (n=6..23)
0x1878 CTRL_CORE_PADCONF_WAKEUPEVENT_4 ro
  [31-n] RGMII0_RXD{n}_DUPLICATEWAKEUPEVENT (n=0..3), [27] RGMII0_RXCTL_DUPLICATEWAKEUPEVENT, [26] RGMII0_RXC_DUPLICATEWAKEUPEVENT, [25-n] RGMII0_TXD{n}_DUPLICATEWAKEUPEVENT (n=0..3), [21] RGMII0_TXCTL_DUPLICATEWAKEUPEVENT, [20] RGMII0_TXC_DUPLICATEWAKEUPEVENT, [19] UART3_TXD_DUPLICATEWAKEUPEVENT, [18] UART3_RXD_DUPLICATEWAKEUPEVENT, [17] RMII_MHZ_50_CLK_DUPLICATEWAKEUPEVENT, [16] MDIO_D_DUPLICATEWAKEUPEVENT, [15] MDIO_MCLK_DUPLICATEWAKEUPEVENT, [n-9] VOUT1_D{n}_DUPLICATEWAKEUPEVENT (n=9..23)
0x187C CTRL_CORE_PADCONF_WAKEUPEVENT_5 ro
  [31] MCASP2_ACLKR_DUPLICATEWAKEUPEVENT, [30] MCASP2_FSX_DUPLICATEWAKEUPEVENT, [29] MCASP2_ACLKX_DUPLICATEWAKEUPEVENT, [n+13] MCASP1_AXR{n}_DUPLICATEWAKEUPEVENT (n=0..15), [12] MCASP1_FSR_DUPLICATEWAKEUPEVENT, [11] MCASP1_ACLKR_DUPLICATEWAKEUPEVENT, [10] MCASP1_FSX_DUPLICATEWAKEUPEVENT, [9] MCASP1_ACLKX_DUPLICATEWAKEUPEVENT, [n+5] XREF_CLK{n}_DUPLICATEWAKEUPEVENT (n=0..3), [4] GPIO6_16_DUPLICATEWAKEUPEVENT, [3] GPIO6_15_DUPLICATEWAKEUPEVENT, [2] GPIO6_14_DUPLICATEWAKEUPEVENT, [1] USB2_DRVVBUS_DUPLICATEWAKEUPEVENT, [0] USB1_DRVVBUS_DUPLICATEWAKEUPEVENT
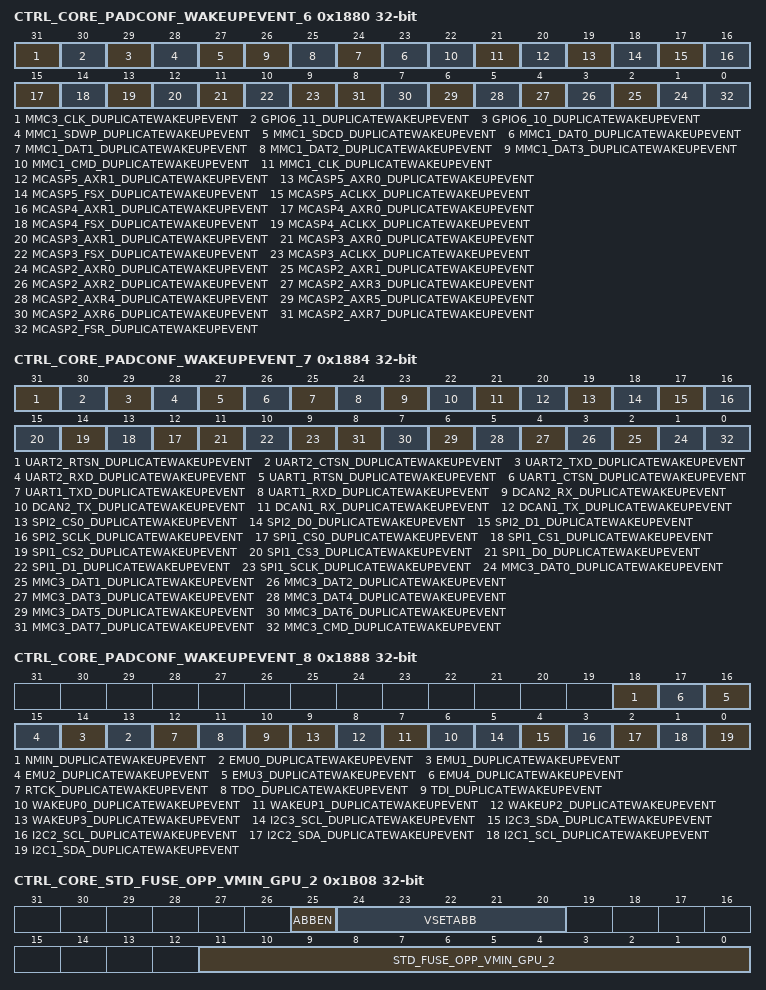
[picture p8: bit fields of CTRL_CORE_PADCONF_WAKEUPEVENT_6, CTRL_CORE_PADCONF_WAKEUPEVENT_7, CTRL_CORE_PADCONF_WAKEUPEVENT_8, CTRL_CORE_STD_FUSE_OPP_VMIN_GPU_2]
0x1880 CTRL_CORE_PADCONF_WAKEUPEVENT_6 ro
  [31] MMC3_CLK_DUPLICATEWAKEUPEVENT, [30] GPIO6_11_DUPLICATEWAKEUPEVENT, [29] GPIO6_10_DUPLICATEWAKEUPEVENT, [28] MMC1_SDWP_DUPLICATEWAKEUPEVENT, [27] MMC1_SDCD_DUPLICATEWAKEUPEVENT, [n+23] MMC1_DAT{n}_DUPLICATEWAKEUPEVENT (n=0..3), [22] MMC1_CMD_DUPLICATEWAKEUPEVENT, [21] MMC1_CLK_DUPLICATEWAKEUPEVENT, [20] MCASP5_AXR1_DUPLICATEWAKEUPEVENT, [19] MCASP5_AXR0_DUPLICATEWAKEUPEVENT, [18] MCASP5_FSX_DUPLICATEWAKEUPEVENT, [17] MCASP5_ACLKX_DUPLICATEWAKEUPEVENT, [16] MCASP4_AXR1_DUPLICATEWAKEUPEVENT, [15] MCASP4_AXR0_DUPLICATEWAKEUPEVENT, [14] MCASP4_FSX_DUPLICATEWAKEUPEVENT, [13] MCASP4_ACLKX_DUPLICATEWAKEUPEVENT, [12] MCASP3_AXR1_DUPLICATEWAKEUPEVENT, [11] MCASP3_AXR0_DUPLICATEWAKEUPEVENT, [10] MCASP3_FSX_DUPLICATEWAKEUPEVENT, [9] MCASP3_ACLKX_DUPLICATEWAKEUPEVENT, [n+1] MCASP2_AXR{n}_DUPLICATEWAKEUPEVENT (n=0..7), [0] MCASP2_FSR_DUPLICATEWAKEUPEVENT
0x1884 CTRL_CORE_PADCONF_WAKEUPEVENT_7 ro
  [31] UART2_RTSN_DUPLICATEWAKEUPEVENT, [30] UART2_CTSN_DUPLICATEWAKEUPEVENT, [29] UART2_TXD_DUPLICATEWAKEUPEVENT, [28] UART2_RXD_DUPLICATEWAKEUPEVENT, [27] UART1_RTSN_DUPLICATEWAKEUPEVENT, [26] UART1_CTSN_DUPLICATEWAKEUPEVENT, [25] UART1_TXD_DUPLICATEWAKEUPEVENT, [24] UART1_RXD_DUPLICATEWAKEUPEVENT, [23] DCAN2_RX_DUPLICATEWAKEUPEVENT, [22] DCAN2_TX_DUPLICATEWAKEUPEVENT, [21] DCAN1_RX_DUPLICATEWAKEUPEVENT, [20] DCAN1_TX_DUPLICATEWAKEUPEVENT, [19] SPI2_CS0_DUPLICATEWAKEUPEVENT, [18] SPI2_D0_DUPLICATEWAKEUPEVENT, [17] SPI2_D1_DUPLICATEWAKEUPEVENT, [16] SPI2_SCLK_DUPLICATEWAKEUPEVENT, [n+12] SPI1_CS{n}_DUPLICATEWAKEUPEVENT (n=0..3), [11] SPI1_D0_DUPLICATEWAKEUPEVENT, [10] SPI1_D1_DUPLICATEWAKEUPEVENT, [9] SPI1_SCLK_DUPLICATEWAKEUPEVENT, [n+1] MMC3_DAT{n}_DUPLICATEWAKEUPEVENT (n=0..7), [0] MMC3_CMD_DUPLICATEWAKEUPEVENT
0x1888 CTRL_CORE_PADCONF_WAKEUPEVENT_8 ro
  [18] NMIN_DUPLICATEWAKEUPEVENT, [n+13] EMU{n}_DUPLICATEWAKEUPEVENT (n=0..4), [12] RTCK_DUPLICATEWAKEUPEVENT, [11] TDO_DUPLICATEWAKEUPEVENT, [10] TDI_DUPLICATEWAKEUPEVENT, [n+6] WAKEUP{n}_DUPLICATEWAKEUPEVENT (n=0..3), [5] I2C3_SCL_DUPLICATEWAKEUPEVENT, [4] I2C3_SDA_DUPLICATEWAKEUPEVENT, [3] I2C2_SCL_DUPLICATEWAKEUPEVENT, [2] I2C2_SDA_DUPLICATEWAKEUPEVENT, [1] I2C1_SCL_DUPLICATEWAKEUPEVENT, [0] I2C1_SDA_DUPLICATEWAKEUPEVENT
0x1B08 CTRL_CORE_STD_FUSE_OPP_VMIN_GPU_2 ro reset not defined — This register contains the AVS Class 0 voltage value for the vdd_gpu voltage rail when running at OPP_NOM. This register also stores information about ABB configuration for that OPP.
  [25] ABBEN
    0=ABB_disabled (ABB is disabled); 1=ABB_enabled (ABB is enabled)
  [24:20] VSETABB — This bit field shows the ABB LDO target value for OPP_NOM which has to be written to theCTRL_WKUP_LDOVBB_GPU_VOLTAGE_CTRL [4:0] LDOVBBGPU_FBB_VSET_OUT bit field, if ABB is enabled.
  [11:0] STD_FUSE_OPP_VMIN_GPU_2 — AVS Class 0 voltage value for the vdd_gpu voltage rail when running at OPP_NOM. To get the actual value in mV, the value read from this bit field must be converted to decimal value.
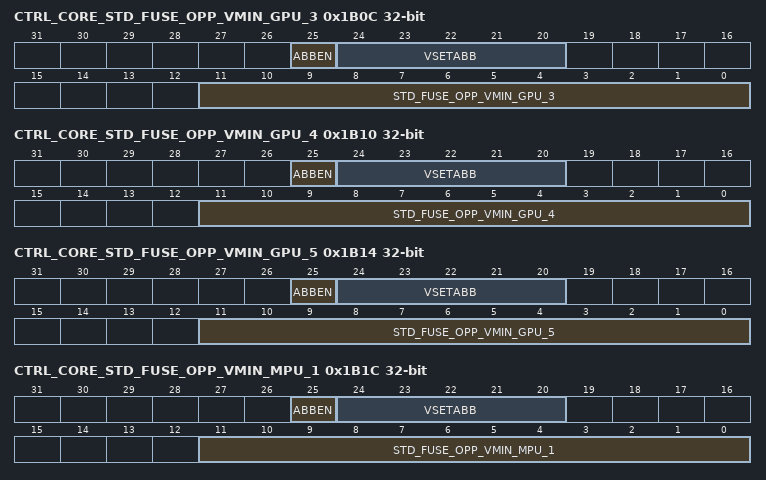
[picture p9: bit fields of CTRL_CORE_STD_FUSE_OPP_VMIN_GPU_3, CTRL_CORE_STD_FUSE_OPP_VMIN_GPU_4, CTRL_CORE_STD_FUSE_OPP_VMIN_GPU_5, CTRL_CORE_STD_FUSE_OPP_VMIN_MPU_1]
0x1B0C CTRL_CORE_STD_FUSE_OPP_VMIN_GPU_3 ro reset not defined — This register contains the AVS Class 0 voltage value for the vdd_gpu voltage rail when running at OPP_OD. This register also stores information about ABB configuration for that OPP.
  [25] ABBEN
    values as CTRL_CORE_STD_FUSE_OPP_VMIN_GPU_2.ABBEN
  [24:20] VSETABB — This bit field shows the ABB LDO target value for OPP_OD which has to be written to theCTRL_WKUP_LDOVBB_GPU_VOLTAGE_CTRL [4:0] LDOVBBGPU_FBB_VSET_OUT bit field, if ABB is enabled.
  [11:0] STD_FUSE_OPP_VMIN_GPU_3 — AVS Class 0 voltage value for the vdd_gpu voltage rail when running at OPP_OD. To get the actual value in mV, the value read from this bit field must be converted to decimal value.
0x1B10 CTRL_CORE_STD_FUSE_OPP_VMIN_GPU_4 ro reset not defined — This register contains the AVS Class 0 voltage value for the vdd_gpu voltage rail when running at OPP_HIGH. This register also stores information about ABB configuration for that OPP.
  [25] ABBEN
    values as CTRL_CORE_STD_FUSE_OPP_VMIN_GPU_2.ABBEN
  [24:20] VSETABB — This bit field shows the ABB LDO target value for OPP_HIGH which has to be written to theCTRL_WKUP_LDOVBB_GPU_VOLTAGE_CTRL [4:0] LDOVBBGPU_FBB_VSET_OUT bit field, if ABB is enabled.
  [11:0] STD_FUSE_OPP_VMIN_GPU_4 — AVS Class 0 voltage value for the vdd_gpu voltage rail when running at OPP_HIGH. To get the actual value in mV, the value read from this bit field must be converted to decimal value.
0x1B14 CTRL_CORE_STD_FUSE_OPP_VMIN_GPU_5 ro reset not defined — This register contains the AVS Class 0 voltage value for the vdd_gpu voltage rail when running at OPP_PLUS. This register also stores information about ABB configuration for that OPP.
  [25] ABBEN
    values as CTRL_CORE_STD_FUSE_OPP_VMIN_GPU_2.ABBEN
  [24:20] VSETABB — This bit field shows the ABB LDO target value for OPP_PLUS which has to be written to theCTRL_WKUP_LDOVBB_GPU_VOLTAGE_CTRL [4:0] LDOVBBGPU_FBB_VSET_OUT bit field, if ABB is enabled.
  [11:0] STD_FUSE_OPP_VMIN_GPU_5 — AVS Class 0 voltage value for the vdd_gpu voltage rail when running at OPP_PLUS. To get the actual value in mV, the value read from this bit field must be converted to decimal value.
0x1B1C CTRL_CORE_STD_FUSE_OPP_VMIN_MPU_1 ro reset not defined — This register contains the AVS Class 0 voltage value for the vdd_mpu voltage rail when running at OPP_LOW. This register also stores information about ABB configuration for that OPP.
  [25] ABBEN
    values as CTRL_CORE_STD_FUSE_OPP_VMIN_GPU_2.ABBEN
  [24:20] VSETABB — This bit field shows the ABB LDO target value for OPP_LOW which has to be written to theCTRL_WKUP_LDOVBB_MPU_VOLTAGE_CTRL[4:0] LDOVBBMPU_FBB_VSET_OUT bit field, if ABB is enabled.
  [11:0] STD_FUSE_OPP_VMIN_MPU_1 — AVS Class 0 voltage value for the vdd_mpu voltage rail when running at OPP_LOW. To get the actual value in mV, the value read from this bit field must be converted to decimal value.
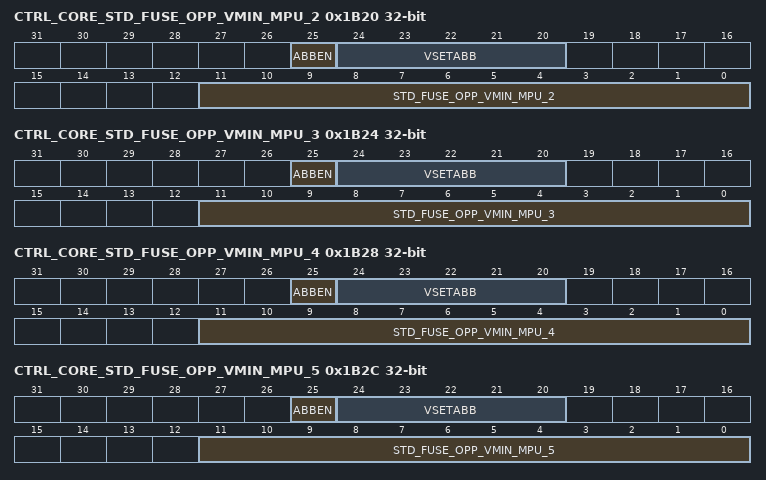
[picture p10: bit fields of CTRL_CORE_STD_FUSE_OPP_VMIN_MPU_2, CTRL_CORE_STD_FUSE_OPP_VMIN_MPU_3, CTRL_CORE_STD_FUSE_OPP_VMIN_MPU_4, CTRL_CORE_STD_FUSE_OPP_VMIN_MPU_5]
0x1B20 CTRL_CORE_STD_FUSE_OPP_VMIN_MPU_2 ro reset not defined — This register contains the AVS Class 0 voltage value for the vdd_mpu voltage rail when running at OPP_NOM. This register also stores information about ABB configuration for that OPP.
  [25] ABBEN
    values as CTRL_CORE_STD_FUSE_OPP_VMIN_GPU_2.ABBEN
  [24:20] VSETABB — This bit field shows the ABB LDO target value for OPP_NOM which has to be written to theCTRL_WKUP_LDOVBB_MPU_VOLTAGE_CTRL[4:0] LDOVBBMPU_FBB_VSET_OUT bit field, if ABB is enabled.
  [11:0] STD_FUSE_OPP_VMIN_MPU_2 — AVS Class 0 voltage value for the vdd_mpu voltage rail when running at OPP_NOM. To get the actual value in mV, the value read from this bit field must be converted to decimal value.
0x1B24 CTRL_CORE_STD_FUSE_OPP_VMIN_MPU_3 ro reset not defined — This register contains the AVS Class 0 voltage value for the vdd_mpu voltage rail when running at OPP_OD. This register also stores information about ABB configuration for that OPP.
  [25] ABBEN
    values as CTRL_CORE_STD_FUSE_OPP_VMIN_GPU_2.ABBEN
  [24:20] VSETABB — This bit field shows the ABB LDO target value for OPP_OD which has to be written to theCTRL_WKUP_LDOVBB_MPU_VOLTAGE_CTRL[4:0] LDOVBBMPU_FBB_VSET_OUT bit field, if ABB is enabled.
  [11:0] STD_FUSE_OPP_VMIN_MPU_3 — AVS Class 0 voltage value for the vdd_mpu voltage rail when running at OPP_OD. To get the actual value in mV, the value read from this bit field must be converted to decimal value.
0x1B28 CTRL_CORE_STD_FUSE_OPP_VMIN_MPU_4 ro reset not defined — This register contains the AVS Class 0 voltage value for the vdd_mpu voltage rail when running at OPP_HIGH. This register also stores information about ABB configuration for that OPP.
  [25] ABBEN
    values as CTRL_CORE_STD_FUSE_OPP_VMIN_GPU_2.ABBEN
  [24:20] VSETABB — This bit field shows the ABB LDO target value for OPP_HIGH which has to be written to theCTRL_WKUP_LDOVBB_MPU_VOLTAGE_CTRL[4:0] LDOVBBMPU_FBB_VSET_OUT bit field, if ABB is enabled.
  [11:0] STD_FUSE_OPP_VMIN_MPU_4 — AVS Class 0 voltage value for the vdd_mpu voltage rail when running at OPP_HIGH. To get the actual value in mV, the value read from this bit field must be converted to decimal value.
0x1B2C CTRL_CORE_STD_FUSE_OPP_VMIN_MPU_5 ro reset not defined — This register contains the AVS Class 0 voltage value for the vdd_mpu voltage rail when running at OPP_PLUS. This register also stores information about ABB configuration for that OPP.
  [25] ABBEN
    values as CTRL_CORE_STD_FUSE_OPP_VMIN_GPU_2.ABBEN
  [24:20] VSETABB — This bit field shows the ABB LDO target value for OPP_PLUS which has to be written to theCTRL_WKUP_LDOVBB_MPU_VOLTAGE_CTRL[4:0] LDOVBBMPU_FBB_VSET_OUT bit field, if ABB is enabled.
  [11:0] STD_FUSE_OPP_VMIN_MPU_5 — AVS Class 0 voltage value for the vdd_mpu voltage rail when running at OPP_PLUS. To get the actual value in mV, the value read from this bit field must be converted to decimal value.
{0x1B38+4i} CTRL_CORE_STD_FUSE_OPP_VDD_DSPEVE_LVT_{i} ro (i=0..4) — Standard Fuse OPP VDD_GPU [{32i+31}:{32i}]. Register shows part of the chip eFuse configuration on the OCP interface. Reading at the address of one of these registers provides a direct view into a part of the eFuse chain.
  [31:0] STD_FUSE_OPP_VDD_DSPEVE_LVT_{i}
{0x1B4C+4i} CTRL_CORE_STD_FUSE_OPP_VDD_IVA_LVT_{i} ro (i=0..4) — Standard Fuse OPP VDD_IVA [{32i+31}:{32i}]. Register shows part of the chip eFuse configuration on the OCP interface. Reading at the address of one of these registers provides a direct view into a part of the eFuse chain.
  [31:0] STD_FUSE_OPP_VDD_IVA_LVT_{i}
{0x1B60+4i} CTRL_CORE_STD_FUSE_OPP_VDD_CORE_LVT_{i} ro (i=0..4) — Standard Fuse OPP VDD_CORE [{32i+31}:{32i}]. Register shows part of the chip eFuse configuration on the OCP interface. Reading at the address of one of these registers provides a direct view into a part of the eFuse chain.
  [31:0] STD_FUSE_OPP_VDD_CORE_LVT_{i}
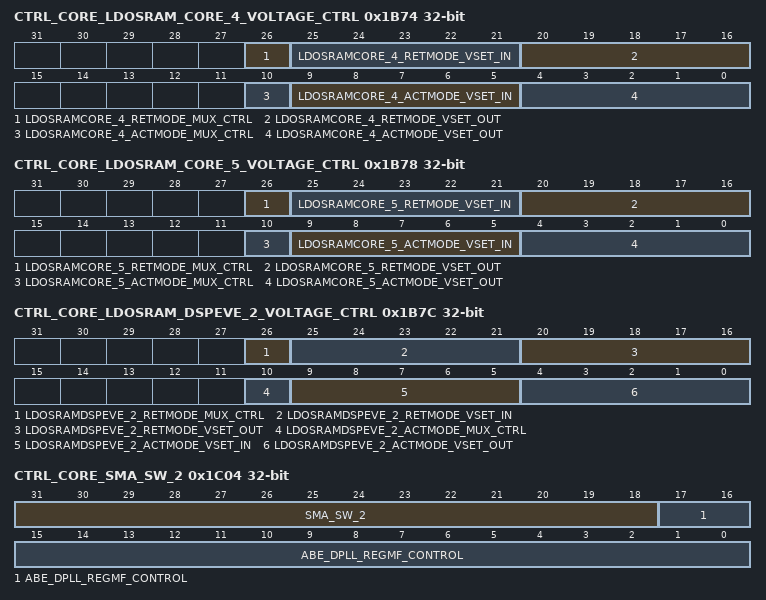
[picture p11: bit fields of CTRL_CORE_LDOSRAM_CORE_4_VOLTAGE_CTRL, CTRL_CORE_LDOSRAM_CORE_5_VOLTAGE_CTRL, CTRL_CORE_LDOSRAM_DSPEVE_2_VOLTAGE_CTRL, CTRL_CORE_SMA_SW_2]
0x1B74 CTRL_CORE_LDOSRAM_CORE_4_VOLTAGE_CTRL — CORE 4th SRAM LDO Control register
  [26] LDOSRAMCORE_4_RETMODE_MUX_CTRL rw — Override control of EFUSE Retention Mode Voltage value
    0=EFUSE (eFuse value is used); 1=OCP (Override value is used)
  [25:21] LDOSRAMCORE_4_RETMODE_VSET_IN ro — EFUSE Retention Mode Voltage value (vset[9:5])
  [20:16] LDOSRAMCORE_4_RETMODE_VSET_OUT rw — Override value for Retention Mode Voltage
  [10] LDOSRAMCORE_4_ACTMODE_MUX_CTRL rw — Override control of EFUSE Active Mode Voltage value
    values as LDOSRAMCORE_4_RETMODE_MUX_CTRL
  [9:5] LDOSRAMCORE_4_ACTMODE_VSET_IN ro — EFUSE Active Mode Voltage value (vset[4:0])
  [4:0] LDOSRAMCORE_4_ACTMODE_VSET_OUT rw — Override value for Active Mode Voltage value
0x1B78 CTRL_CORE_LDOSRAM_CORE_5_VOLTAGE_CTRL — CORE 5th SRAM LDO Control register
  [26] LDOSRAMCORE_5_RETMODE_MUX_CTRL rw — Override control of EFUSE Retention Mode Voltage value
    values as CTRL_CORE_LDOSRAM_CORE_4_VOLTAGE_CTRL.LDOSRAMCORE_4_RETMODE_MUX_CTRL
  [25:21] LDOSRAMCORE_5_RETMODE_VSET_IN ro — EFUSE Retention Mode Voltage value (vset[9:5])
  [20:16] LDOSRAMCORE_5_RETMODE_VSET_OUT rw — Override value for Retention Mode Voltage
  [10] LDOSRAMCORE_5_ACTMODE_MUX_CTRL rw — Override control of EFUSE Active Mode Voltage value
    values as CTRL_CORE_LDOSRAM_CORE_4_VOLTAGE_CTRL.LDOSRAMCORE_4_RETMODE_MUX_CTRL
  [9:5] LDOSRAMCORE_5_ACTMODE_VSET_IN ro — EFUSE Active Mode Voltage value (vset[4:0])
  [4:0] LDOSRAMCORE_5_ACTMODE_VSET_OUT rw — Override value for Active Mode Voltage value
0x1B7C CTRL_CORE_LDOSRAM_DSPEVE_2_VOLTAGE_CTRL — DSPEVE 2nd SRAM LDO Control register
  [26] LDOSRAMDSPEVE_2_RETMODE_MUX_CTRL rw — Override control of EFUSE Retention Mode Voltage value
    values as CTRL_CORE_LDOSRAM_CORE_4_VOLTAGE_CTRL.LDOSRAMCORE_4_RETMODE_MUX_CTRL
  [25:21] LDOSRAMDSPEVE_2_RETMODE_VSET_IN ro — EFUSE Retention Mode Voltage value (vset[9:5])
  [20:16] LDOSRAMDSPEVE_2_RETMODE_VSET_OUT rw — Override value for Retention Mode Voltage
  [10] LDOSRAMDSPEVE_2_ACTMODE_MUX_CTRL rw — Override control of EFUSE Active Mode Voltage value
    values as CTRL_CORE_LDOSRAM_CORE_4_VOLTAGE_CTRL.LDOSRAMCORE_4_RETMODE_MUX_CTRL
  [9:5] LDOSRAMDSPEVE_2_ACTMODE_VSET_IN ro — EFUSE Active Mode Voltage value (vset[4:0])
  [4:0] LDOSRAMDSPEVE_2_ACTMODE_VSET_OUT rw — Override value for Active Mode Voltage value
0x1C04 CTRL_CORE_SMA_SW_2 rw — OCP Spare Register
  [31:18] SMA_SW_2 — Spare bits
  [17:0] ABE_DPLL_REGMF_CONTROL — Fractional part of the software-configured multiplication ratio M of DPLL_ABE. To disable the fractional part this bit field must be set to 0x0.
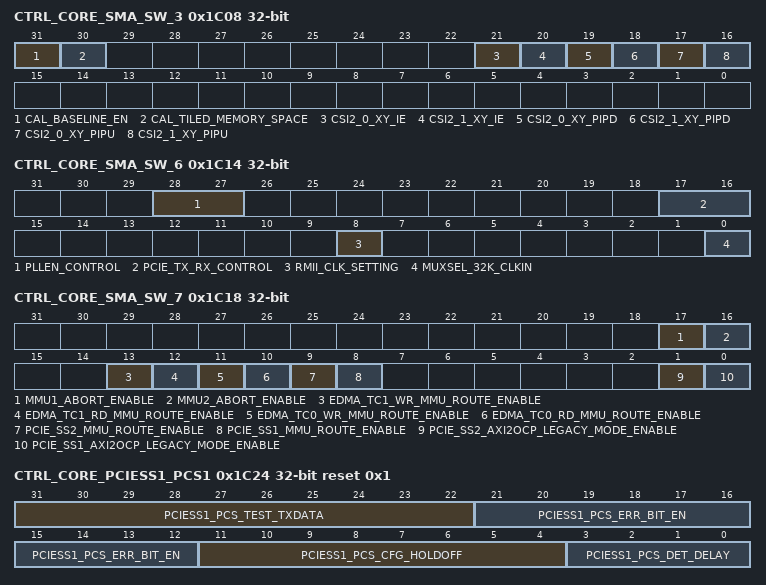
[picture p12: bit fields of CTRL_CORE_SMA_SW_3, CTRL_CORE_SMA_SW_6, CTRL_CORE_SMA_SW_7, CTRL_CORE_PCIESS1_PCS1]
0x1C08 CTRL_CORE_SMA_SW_3 rw — OCP Spare Register
  [31] CAL_BASELINE_EN — CAL baseline enable 0x0: All 4 video ports enabled 0x1: Baseline mode (only video port 1 enabled)
  [30] CAL_TILED_MEMORY_SPACE — This is the 33rd address bit on the L3_MAIN associated with CAL. This bit controls whether CAL performs an access to Q0-Q3 address range or to TILER_VIEW address range. 0x0: The lower 4GiB address space (Q0-Q3) is accessed. 0x1: The address space associated with the 8 TILER views is accessed.
  [21] CSI2_0_XY_IE — Input buffer enable for all DX and DY lanes of CSI2_PHY1. Used when the PHY is configured in GPI mode.
  [20] CSI2_1_XY_IE — Input buffer enable for all DX and DY lanes of CSI2_PHY2. Used when the PHY is configured in GPI mode.
  [19] CSI2_0_XY_PIPD — Pull-down enable (active low) for all DX and DY lanes of CSI2_PHY1. Used when the PHY is configured in GPI mode.
  [18] CSI2_1_XY_PIPD — Pull-down enable (active low) for all DX and DY lanes of CSI2_PHY2. Used when the PHY is configured in GPI mode.
  [17] CSI2_0_XY_PIPU — Pull-up enable (active low) for all DX and DY lanes of CSI2_PHY1. Used when the PHY is configured in GPI mode.
  [16] CSI2_1_XY_PIPU — Pull-up enable (active low) for all DX and DY lanes of CSI2_PHY2. Used when the PHY is configured in GPI mode.
0x1C14 CTRL_CORE_SMA_SW_6 — OCP Spare Register
  [28:27] PLLEN_CONTROL rw — PLLEN control setting. Bit [28] – Controls the CLKOUT of DPLL_USB_OTG. 0x0: CLKOUT is disabled 0x1: CLKOUT is enabled Bit [27] – Controls the CLKOUT of DPLL_SATA 0x0: CLKOUT is disabled 0x1: CLKOUT is enabled
  [17:16] PCIE_TX_RX_CONTROL rw — PCIe RX and TX control of ACSPCIe. 0x0: ACSPCIe Power Down Mode 0x1: ACSPCIe TX Mode 0x2: ACSPCIe RX Mode 0x3: Reserved
  [8] RMII_CLK_SETTING rw — RMII CLK setting 0x0: Internal clock from DPLL_GMAC 0x1: External clock from RMII_MHZ_50_CLK pin
  [0] MUXSEL_32K_CLKIN rw — Setting for mux to select 32KHz clock input to PRCM. This bit must NOT be modified by software. The 32kHz clock selection is done through the device sysboot[9:8] signals.
0x1C18 CTRL_CORE_SMA_SW_7 — OCP Spare Register
  [17] MMU1_ABORT_ENABLE rw
  [16] MMU2_ABORT_ENABLE rw
  [13] EDMA_TC1_WR_MMU_ROUTE_ENABLE rw — EDMA TC1 WR traffic MMU route enable
  [12] EDMA_TC1_RD_MMU_ROUTE_ENABLE rw — EDMA TC1 RD traffic MMU route enable
  [11] EDMA_TC0_WR_MMU_ROUTE_ENABLE rw — EDMA TC0 WR traffic MMU route enable
  [10] EDMA_TC0_RD_MMU_ROUTE_ENABLE rw — EDMA TC0 RD traffic MMU route enable
  [9] PCIE_SS2_MMU_ROUTE_ENABLE rw
  [8] PCIE_SS1_MMU_ROUTE_ENABLE rw
  [1] PCIE_SS2_AXI2OCP_LEGACY_MODE_ENABLE rw
  [0] PCIE_SS1_AXI2OCP_LEGACY_MODE_ENABLE rw
0x1C1C CTRL_CORE_SMA_SW_8 rw — Test control inputs used by the module
  [31:0] PCIE_PLL_TEST_INPUT_1
0x1C20 CTRL_CORE_SMA_SW_9 rw — Test control inputs used by the module
  [31:0] PCIE_PLL_TEST_INPUT_2
0x1C24 CTRL_CORE_PCIESS1_PCS1 rw reset 0x1
  [31:22] PCIESS1_PCS_TEST_TXDATA, [21:12] PCIESS1_PCS_ERR_BIT_EN, [11:4] PCIESS1_PCS_CFG_HOLDOFF, [3:0] PCIESS1_PCS_DET_DELAY
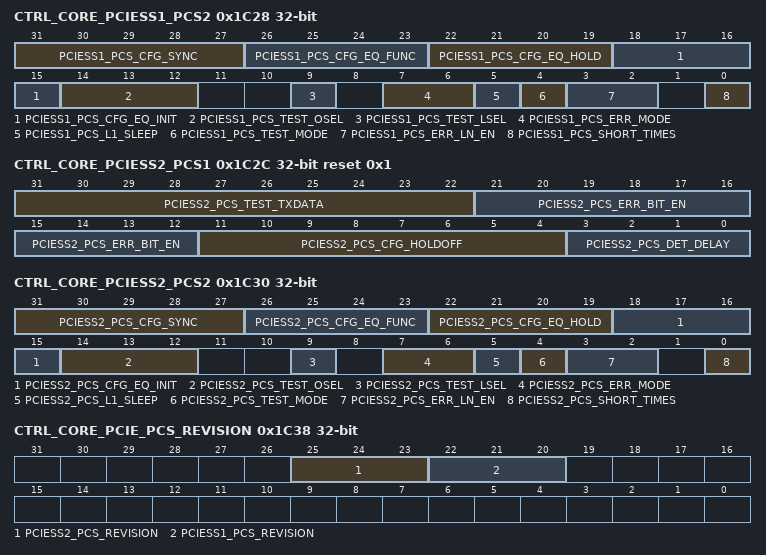
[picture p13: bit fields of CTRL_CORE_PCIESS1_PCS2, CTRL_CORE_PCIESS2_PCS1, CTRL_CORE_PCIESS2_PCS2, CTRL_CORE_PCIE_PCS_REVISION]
0x1C28 CTRL_CORE_PCIESS1_PCS2
  [31:27] PCIESS1_PCS_CFG_SYNC rw, [26:23] PCIESS1_PCS_CFG_EQ_FUNC rw, [22:19] PCIESS1_PCS_CFG_EQ_HOLD rw, [18:15] PCIESS1_PCS_CFG_EQ_INIT rw, [14:12] PCIESS1_PCS_TEST_OSEL rw, [9] PCIESS1_PCS_TEST_LSEL rw, [7:6] PCIESS1_PCS_ERR_MODE rw, [5] PCIESS1_PCS_L1_SLEEP rw, [4] PCIESS1_PCS_TEST_MODE rw, [3:2] PCIESS1_PCS_ERR_LN_EN rw, [0] PCIESS1_PCS_SHORT_TIMES rw
0x1C2C CTRL_CORE_PCIESS2_PCS1 rw reset 0x1
  [31:22] PCIESS2_PCS_TEST_TXDATA, [21:12] PCIESS2_PCS_ERR_BIT_EN, [11:4] PCIESS2_PCS_CFG_HOLDOFF, [3:0] PCIESS2_PCS_DET_DELAY
0x1C30 CTRL_CORE_PCIESS2_PCS2
  [31:27] PCIESS2_PCS_CFG_SYNC rw, [26:23] PCIESS2_PCS_CFG_EQ_FUNC rw, [22:19] PCIESS2_PCS_CFG_EQ_HOLD rw, [18:15] PCIESS2_PCS_CFG_EQ_INIT rw, [14:12] PCIESS2_PCS_TEST_OSEL rw, [9] PCIESS2_PCS_TEST_LSEL rw, [7:6] PCIESS2_PCS_ERR_MODE rw, [5] PCIESS2_PCS_L1_SLEEP rw, [4] PCIESS2_PCS_TEST_MODE rw, [3:2] PCIESS2_PCS_ERR_LN_EN rw, [0] PCIESS2_PCS_SHORT_TIMES rw
0x1C34 CTRL_CORE_PCIE_PCS
  [23:16] PCIESS_PCS_RC_DELAY_COUNT rw — Set to 0x96 for proper functional and compliance-mode behavior on both PCIESS1 and PCIESS2.
0x1C38 CTRL_CORE_PCIE_PCS_REVISION ro — pcs_revision
  [25:23] PCIESS2_PCS_REVISION, [22:20] PCIESS1_PCS_REVISION
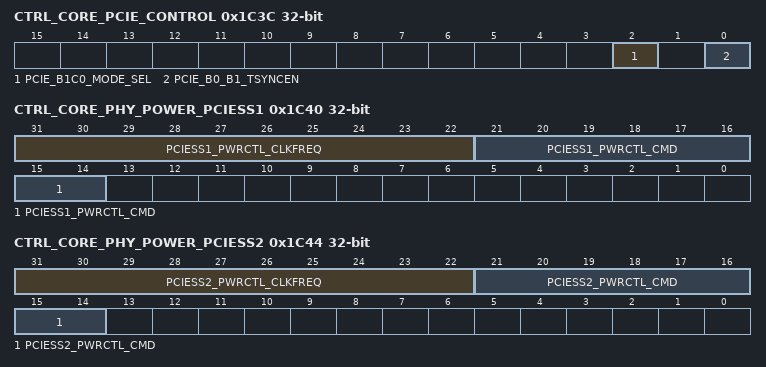
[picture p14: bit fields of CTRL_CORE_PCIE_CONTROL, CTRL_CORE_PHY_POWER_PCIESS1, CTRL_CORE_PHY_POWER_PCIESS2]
0x1C3C CTRL_CORE_PCIE_CONTROL — serdes control selection PCIE C0 (0 default) vs PCIE B1 (1)
  [2] PCIE_B1C0_MODE_SEL rw — 0x0: PCIESS1 x1 Mode and/or PCIESS2 x1 Mode 0x1: PCIESS1 x2 Mode, PCIESS2 Unused
  [0] PCIE_B0_B1_TSYNCEN rw — 0x0: PCIESS1 x1 Mode and/or PCIESS2 x1 Mode 0x1: PCIESS1 x2 Mode, PCIESS2 Unused
0x1C40 CTRL_CORE_PHY_POWER_PCIESS1
  [31:22] PCIESS1_PWRCTL_CLKFREQ rw — Frequency of SYSCLK1 in MHz (rounded). For example, for 20MHz, program 0x14.
  [21:14] PCIESS1_PWRCTL_CMD rw — Powers up/down the PCIESS1_PHY_TX and PCIESS1_PHY_RX modules. 0x0: Powers down PCIESS1_PHY_TX and PCIESS1_PHY_RX 0x1: Powers up PCIESS1_PHY_RX 0x2: Powers up PCIESS1_PHY_TX 0x3: Powers up PCIESS1_PHY_TX and PCIESS1_PHY_RX 0x4-0xFF: Reserved
0x1C44 CTRL_CORE_PHY_POWER_PCIESS2
  [31:22] PCIESS2_PWRCTL_CLKFREQ rw — Frequency of SYSCLK1 in MHz (rounded). For example, for 20MHz, program 0x14.
  [21:14] PCIESS2_PWRCTL_CMD rw — Powers up/down the PCIESS2_PHY_TX and PCIESS2_PHY_RX modules. 0x0: Powers down PCIESS2_PHY_TX and PCIESS2_PHY_RX 0x1: Powers up PCIESS2_PHY_RX 0x2: Powers up PCIESS2_PHY_TX 0x3: Powers up PCIESS2_PHY_TX and PCIESS2_PHY_RX 0x4-0xFF: Reserved
